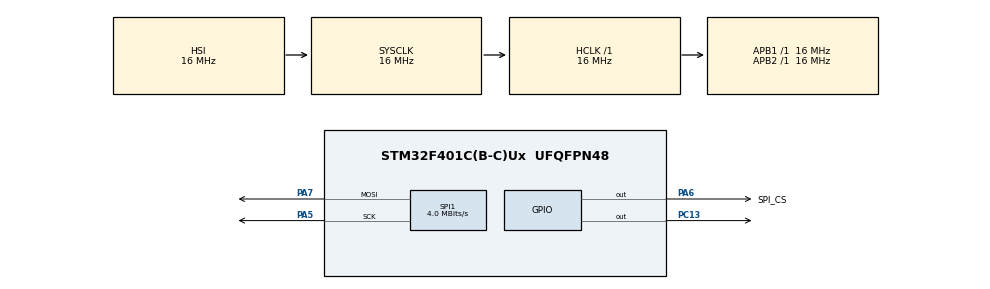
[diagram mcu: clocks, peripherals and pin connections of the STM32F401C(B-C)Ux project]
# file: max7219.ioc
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Mcu.Family=STM32F4
Mcu.Name=STM32F401C(B-C)Ux
Mcu.Package=UFQFPN48
NVIC.PriorityGroup=NVIC_PRIORITYGROUP_4
PA13.Mode=Serial_Wire
PA13.Signal=SYS_JTMS-SWDIO
PA14.Mode=Serial_Wire
PA14.Signal=SYS_JTCK-SWCLK
PA5.Mode=TX_Only_Simplex_Unidirect_Master
PA5.Signal=SPI1_SCK
PA6.GPIO_Label=SPI_CS
PA6.Signal=GPIO_Output
PA7.Mode=TX_Only_Simplex_Unidirect_Master
PA7.Signal=SPI1_MOSI
PC13-ANTI_TAMP.Signal=GPIO_Output
ProjectManager.HeapSize=0x200
ProjectManager.StackSize=0x400
ProjectManager.TargetToolchain=STM32CubeIDE
RCC.AHBFreq_Value=16000000
RCC.APB1Freq_Value=16000000
RCC.APB2Freq_Value=16000000
RCC.CortexFreq_Value=16000000
RCC.HSE_VALUE=25000000
RCC.HSI_VALUE=16000000
RCC.LSE_VALUE=32768
RCC.SYSCLKFreq_VALUE=16000000
RCC.VCOOutputFreq_Value=192000000
SPI1.BaudRatePrescaler=SPI_BAUDRATEPRESCALER_4
SPI1.CalculateBaudRate=4.0 MBits/s
SPI1.Direction=SPI_DIRECTION_2LINES
SPI1.Mode=SPI_MODE_MASTER
SPI1.VirtualType=VM_MASTER
board=custom

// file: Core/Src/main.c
/* USER CODE BEGIN Header */
/**
  ******************************************************************************
  * @file           : main.c
  * @brief          : Main program body
  ******************************************************************************
  * @attention
  *
  * Copyright (c) 2025 STMicroelectronics.
  * All rights reserved.
  *
  * This software is licensed under terms that can be found in the LICENSE file
  * in the root directory of this software component.
  * If no LICENSE file comes with this software, it is provided AS-IS.
  *
  ******************************************************************************
  */
/* USER CODE END Header */
#include "main.h"
#include "max7219.h"

SPI_HandleTypeDef hspi1;

void SystemClock_Config(void);
static void MX_GPIO_Init(void);
static void MX_SPI1_Init(void);
/* USER CODE BEGIN PFP */
/*void max7219_write_reg(uint8_t reg_adr, uint8_t data);
void max7219_init(void);*/
/* USER CODE END PFP */

int main(void)
{

  /* MCU Configuration--------------------------------------------------------*/

  /* Reset of all peripherals, Initializes the Flash interface and the Systick. */
  HAL_Init();

  /* Configure the system clock */
  SystemClock_Config();

  /* Initialize all configured peripherals */
  MX_GPIO_Init();
  MX_SPI1_Init();
  /* USER CODE BEGIN 2 */
  MAX7219_Init();
  const uint8_t smile[] =
  {
    0x00, 0x66, 0x66, 0x00, 0x81, 0x42, 0x3c, 0x00
  };
  /* USER CODE END 2 */

  /* Infinite loop */
  /* USER CODE BEGIN WHILE */
  while (1)
  {

	  //max7219_write_reg(0x01, 0x01);
	  for (int i=1; i<=8; i++)
	  {
	     MAX7219_Write(i, smile[8-i]);
	     HAL_Delay(500);
	  }
	  //max7219_write_reg(0xAA, 0b00001111);
	  //HAL_Delay(200);
    /* USER CODE END WHILE */

  }
}

void SystemClock_Config(void)
{
  RCC_OscInitTypeDef RCC_OscInitStruct = {0};
  RCC_ClkInitTypeDef RCC_ClkInitStruct = {0};

  /** Configure the main internal regulator output voltage
  */
  __HAL_RCC_PWR_CLK_ENABLE();
  __HAL_PWR_VOLTAGESCALING_CONFIG(PWR_REGULATOR_VOLTAGE_SCALE2);

  /** Initializes the RCC Oscillators according to the specified parameters
  * in the RCC_OscInitTypeDef structure.
  */
  RCC_OscInitStruct.OscillatorType = RCC_OSCILLATORTYPE_HSI;
  RCC_OscInitStruct.HSIState = RCC_HSI_ON;
  RCC_OscInitStruct.HSICalibrationValue = RCC_HSICALIBRATION_DEFAULT;
  RCC_OscInitStruct.PLL.PLLState = RCC_PLL_NONE;
  if (HAL_RCC_OscConfig(&RCC_OscInitStruct) != HAL_OK)
  {
    Error_Handler();
  }

  /** Initializes the CPU, AHB and APB buses clocks
  */
  RCC_ClkInitStruct.ClockType = RCC_CLOCKTYPE_HCLK|RCC_CLOCKTYPE_SYSCLK
                              |RCC_CLOCKTYPE_PCLK1|RCC_CLOCKTYPE_PCLK2;
  RCC_ClkInitStruct.SYSCLKSource = RCC_SYSCLKSOURCE_HSI;
  RCC_ClkInitStruct.AHBCLKDivider = RCC_SYSCLK_DIV1;
  RCC_ClkInitStruct.APB1CLKDivider = RCC_HCLK_DIV1;
  RCC_ClkInitStruct.APB2CLKDivider = RCC_HCLK_DIV1;

  if (HAL_RCC_ClockConfig(&RCC_ClkInitStruct, FLASH_LATENCY_0) != HAL_OK)
  {
    Error_Handler();
  }
}

static void MX_SPI1_Init(void)
{

  /* SPI1 parameter configuration*/
  hspi1.Instance = SPI1;
  hspi1.Init.Mode = SPI_MODE_MASTER;
  hspi1.Init.Direction = SPI_DIRECTION_2LINES;
  hspi1.Init.DataSize = SPI_DATASIZE_8BIT;
  hspi1.Init.CLKPolarity = SPI_POLARITY_LOW;
  hspi1.Init.CLKPhase = SPI_PHASE_1EDGE;
  hspi1.Init.NSS = SPI_NSS_SOFT;
  hspi1.Init.BaudRatePrescaler = SPI_BAUDRATEPRESCALER_4;
  hspi1.Init.FirstBit = SPI_FIRSTBIT_MSB;
  hspi1.Init.TIMode = SPI_TIMODE_DISABLE;
  hspi1.Init.CRCCalculation = SPI_CRCCALCULATION_DISABLE;
  hspi1.Init.CRCPolynomial = 10;
  if (HAL_SPI_Init(&hspi1) != HAL_OK)
  {
    Error_Handler();
  }

}

static void MX_GPIO_Init(void)
{
  GPIO_InitTypeDef GPIO_InitStruct = {0};

  /* GPIO Ports Clock Enable */
  __HAL_RCC_GPIOC_CLK_ENABLE();
  __HAL_RCC_GPIOA_CLK_ENABLE();

  /*Configure GPIO pin Output Level */
  HAL_GPIO_WritePin(GPIOC, GPIO_PIN_13, GPIO_PIN_RESET);

  /*Configure GPIO pin Output Level */
  HAL_GPIO_WritePin(SPI_CS_GPIO_Port, SPI_CS_Pin, GPIO_PIN_RESET);

  /*Configure GPIO pin : PC13 */
  GPIO_InitStruct.Pin = GPIO_PIN_13;
  GPIO_InitStruct.Mode = GPIO_MODE_OUTPUT_PP;
  GPIO_InitStruct.Pull = GPIO_NOPULL;
  GPIO_InitStruct.Speed = GPIO_SPEED_FREQ_LOW;
  HAL_GPIO_Init(GPIOC, &GPIO_InitStruct);

  /*Configure GPIO pin : SPI_CS_Pin */
  GPIO_InitStruct.Pin = SPI_CS_Pin;
  GPIO_InitStruct.Mode = GPIO_MODE_OUTPUT_PP;
  GPIO_InitStruct.Pull = GPIO_NOPULL;
  GPIO_InitStruct.Speed = GPIO_SPEED_FREQ_LOW;
  HAL_GPIO_Init(SPI_CS_GPIO_Port, &GPIO_InitStruct);

}

/* USER CODE BEGIN 4 */
/*void max7219_write_reg(uint8_t reg_adr, uint8_t data)
{
	uint8_t buff[2] = {reg_adr, data};
	HAL_GPIO_WritePin(SPI_CS_GPIO_Port, SPI_CS_Pin, GPIO_PIN_RESET);
	HAL_SPI_Transmit(&hspi1, buff, sizeof(buff)/sizeof(buff[0]), HAL_MAX_DELAY);
	HAL_GPIO_WritePin(SPI_CS_GPIO_Port, SPI_CS_Pin, GPIO_PIN_SET);
}*/

/*void max7219_init(void)
{
	max7219_write_reg(0x09, 0x00);
	max7219_write_reg(0x0A, 0x0F);
	max7219_write_reg(0x0B, 0x07);
	max7219_write_reg(0x0C, 0x01);
	max7219_write_reg(0x0F, 0x01);
	HAL_Delay(500);
	max7219_write_reg(0x0F, 0x00);
}*/
/* USER CODE END 4 */

void Error_Handler(void)
{
  __disable_irq();
  while (1)
  {
  }
}
